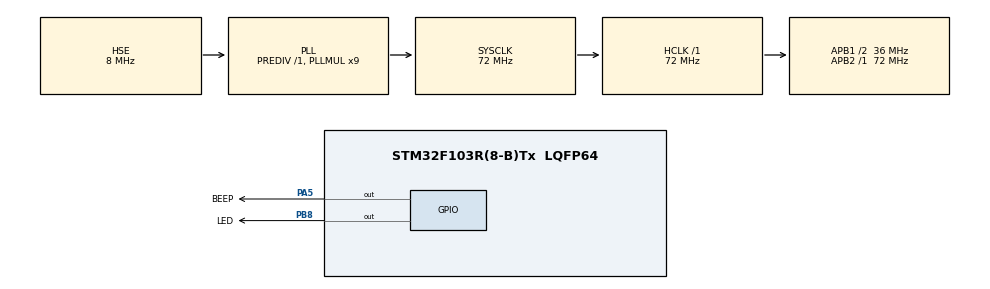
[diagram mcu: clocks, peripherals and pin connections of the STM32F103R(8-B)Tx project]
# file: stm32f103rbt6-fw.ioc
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Mcu.Family=STM32F1
Mcu.Name=STM32F103R(8-B)Tx
Mcu.Package=LQFP64
NVIC.PriorityGroup=NVIC_PRIORITYGROUP_4
PA13.Mode=Serial_Wire
PA13.Signal=SYS_JTMS-SWDIO
PA14.Mode=Serial_Wire
PA14.Signal=SYS_JTCK-SWCLK
PA5.GPIO_Label=BEEP
PA5.Signal=GPIO_Output
PB8.GPIO_Label=LED
PB8.Signal=GPIO_Output
PD0-OSC_IN.Mode=HSE-External-Oscillator
PD0-OSC_IN.Signal=RCC_OSC_IN
PD1-OSC_OUT.Mode=HSE-External-Oscillator
PD1-OSC_OUT.Signal=RCC_OSC_OUT
ProjectManager.HeapSize=0x200
ProjectManager.StackSize=0x400
ProjectManager.TargetToolchain=Makefile
RCC.AHBFreq_Value=72000000
RCC.APB1CLKDivider=RCC_HCLK_DIV2
RCC.APB1Freq_Value=36000000
RCC.APB1TimFreq_Value=72000000
RCC.APB2Freq_Value=72000000
RCC.APB2TimFreq_Value=72000000
RCC.HCLKFreq_Value=72000000
RCC.PLLMUL=RCC_PLL_MUL9
RCC.PLLSourceVirtual=RCC_PLLSOURCE_HSE
RCC.SYSCLKFreq_VALUE=72000000
RCC.SYSCLKSource=RCC_SYSCLKSOURCE_PLLCLK
RCC.USBFreq_Value=72000000
board=custom

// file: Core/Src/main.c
/* USER CODE BEGIN Header */
/**
 ******************************************************************************
 * @file           : main.c
 * @brief          : Main program body
 ******************************************************************************
 * @attention
 *
 * Copyright (c) 2023 STMicroelectronics.
 * All rights reserved.
 *
 * This software is licensed under terms that can be found in the LICENSE file
 * in the root directory of this software component.
 * If no LICENSE file comes with this software, it is provided AS-IS.
 *
 ******************************************************************************
 */
/* USER CODE END Header */
#include "main.h"

/* USER CODE BEGIN Includes */
#include <stdio.h>
/* USER CODE END Includes */

void SystemClock_Config(void);
static void MX_GPIO_Init(void);

/* USER CODE BEGIN 0 */
int _write(int fd, char *ch, int len)
{
  // HAL_UART_Transmit(&huart2, (uint8_t *)ch, len, 0xFFFF);
  return len;
}

/* USER CODE END 0 */

int main(void)
{

  /* MCU Configuration--------------------------------------------------------*/

  /* Reset of all peripherals, Initializes the Flash interface and the Systick. */
  HAL_Init();

  /* Configure the system clock */
  SystemClock_Config();

  /* Initialize all configured peripherals */
  MX_GPIO_Init();

  /* Infinite loop */
  while (1)
  {

    /* USER CODE BEGIN 3 */
    int toneIdx = 0;
    int toneFreq[] = {125,250,500,0}; // 示范指定频率
    int toneTime = 0; // 当前音调的时长
    HAL_GPIO_TogglePin(LED_GPIO_Port, LED_Pin);

    for (toneIdx = 0; toneFreq[toneIdx] != 0; toneIdx++)
    {
      int delayTime = 1000 / toneFreq[toneIdx] / 2;
      for (toneTime = 0; toneTime <= 300; toneTime += delayTime)
      {
        /**********begin**********/

        // HAL_GPIO_TogglePin(BEEP...);
        // HAL_Delay(...);
        //////////////////////////////////////////////////////////////////// PS: The answer is as follows:

        HAL_GPIO_TogglePin(BEEP_GPIO_Port, BEEP_Pin);
        HAL_Delay(500);

        ////////////////////////////////////////////////////////////////////// PS: End of question answer.

        /***********end**********/
      }
    }
    HAL_Delay(200);
  }
  /* USER CODE END 3 */
}

void SystemClock_Config(void)
{
  RCC_OscInitTypeDef RCC_OscInitStruct = {0};
  RCC_ClkInitTypeDef RCC_ClkInitStruct = {0};

  /** Initializes the RCC Oscillators according to the specified parameters
  * in the RCC_OscInitTypeDef structure.
  */
  RCC_OscInitStruct.OscillatorType = RCC_OSCILLATORTYPE_HSE;
  RCC_OscInitStruct.HSEState = RCC_HSE_ON;
  RCC_OscInitStruct.HSEPredivValue = RCC_HSE_PREDIV_DIV1;
  RCC_OscInitStruct.HSIState = RCC_HSI_ON;
  RCC_OscInitStruct.PLL.PLLState = RCC_PLL_ON;
  RCC_OscInitStruct.PLL.PLLSource = RCC_PLLSOURCE_HSE;
  RCC_OscInitStruct.PLL.PLLMUL = RCC_PLL_MUL9;
  if (HAL_RCC_OscConfig(&RCC_OscInitStruct) != HAL_OK)
  {
    Error_Handler();
  }

  /** Initializes the CPU, AHB and APB buses clocks
  */
  RCC_ClkInitStruct.ClockType = RCC_CLOCKTYPE_HCLK|RCC_CLOCKTYPE_SYSCLK
                              |RCC_CLOCKTYPE_PCLK1|RCC_CLOCKTYPE_PCLK2;
  RCC_ClkInitStruct.SYSCLKSource = RCC_SYSCLKSOURCE_PLLCLK;
  RCC_ClkInitStruct.AHBCLKDivider = RCC_SYSCLK_DIV1;
  RCC_ClkInitStruct.APB1CLKDivider = RCC_HCLK_DIV2;
  RCC_ClkInitStruct.APB2CLKDivider = RCC_HCLK_DIV1;

  if (HAL_RCC_ClockConfig(&RCC_ClkInitStruct, FLASH_LATENCY_2) != HAL_OK)
  {
    Error_Handler();
  }
}

static void MX_GPIO_Init(void)
{
  GPIO_InitTypeDef GPIO_InitStruct = {0};

  /* GPIO Ports Clock Enable */
  __HAL_RCC_GPIOD_CLK_ENABLE();
  __HAL_RCC_GPIOA_CLK_ENABLE();
  __HAL_RCC_GPIOB_CLK_ENABLE();

  /*Configure GPIO pin Output Level */
  HAL_GPIO_WritePin(BEEP_GPIO_Port, BEEP_Pin, GPIO_PIN_RESET);

  /*Configure GPIO pin Output Level */
  HAL_GPIO_WritePin(LED_GPIO_Port, LED_Pin, GPIO_PIN_RESET);

  /*Configure GPIO pin : BEEP_Pin */
  GPIO_InitStruct.Pin = BEEP_Pin;
  GPIO_InitStruct.Mode = GPIO_MODE_OUTPUT_PP;
  GPIO_InitStruct.Pull = GPIO_NOPULL;
  GPIO_InitStruct.Speed = GPIO_SPEED_FREQ_LOW;
  HAL_GPIO_Init(BEEP_GPIO_Port, &GPIO_InitStruct);

  /*Configure GPIO pin : LED_Pin */
  GPIO_InitStruct.Pin = LED_Pin;
  GPIO_InitStruct.Mode = GPIO_MODE_OUTPUT_PP;
  GPIO_InitStruct.Pull = GPIO_NOPULL;
  GPIO_InitStruct.Speed = GPIO_SPEED_FREQ_LOW;
  HAL_GPIO_Init(LED_GPIO_Port, &GPIO_InitStruct);

}

void Error_Handler(void)
{
  __disable_irq();
  while (1)
  {
  }
}

#ifdef  USE_FULL_ASSERT
/**
  * @brief  Reports the name of the source file and the source line number
  *         where the assert_param error has occurred.
  * @param  file: pointer to the source file name
  * @param  line: assert_param error line source number
  * @retval None
  */
void assert_failed(uint8_t *file, uint32_t line)
{
  /* USER CODE BEGIN 6 */
  /* User can add his own implementation to report the file name and line number,
     ex: printf("Wrong parameters value: file %s on line %d\r\n", file, line) */
  printf("Wrong parameters value: file %s on line %ld\r\n", file, line);
  /* USER CODE END 6 */
}
#endif /* USE_FULL_ASSERT */
